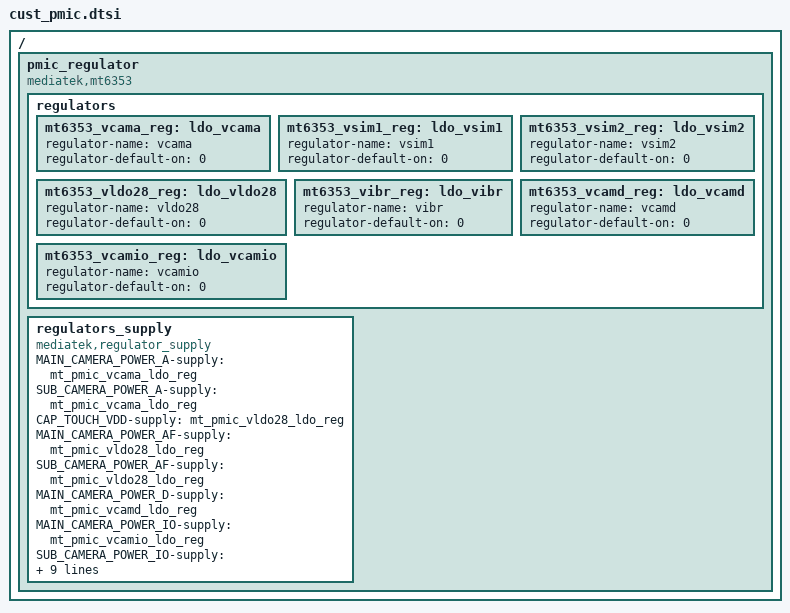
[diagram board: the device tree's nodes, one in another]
/*
 * Generated by MTK SP DrvGen Version 03.13.6 for MT6755. Copyright MediaTek Inc. (C) 2013.
 * Mon Aug 12 22:58:53 2019
 * Do Not Modify the File.
 */

/*************************
 * PMIC DTSI File
*************************/

/ {
	pmic_regulator {
		compatible = "mediatek,mt6353";
		/*reg = <0x01>*/
		regulators {
			mt6353_vcama_reg: ldo_vcama {
				regulator-name = "vcama";
				regulator-default-on = <0>; /* 0:skip, 1: off, 2:on */
			};
			mt6353_vsim1_reg: ldo_vsim1 {
				regulator-name = "vsim1";
				regulator-default-on = <0>; /* 0:skip, 1: off, 2:on */
			};
			mt6353_vsim2_reg: ldo_vsim2 {
				regulator-name = "vsim2";
				regulator-default-on = <0>; /* 0:skip, 1: off, 2:on */
			};
			mt6353_vldo28_reg: ldo_vldo28 {
				regulator-name = "vldo28";
				regulator-default-on = <0>; /* 0:skip, 1: off, 2:on */
			};
			mt6353_vibr_reg: ldo_vibr {
				regulator-name = "vibr";
				regulator-default-on = <0>; /* 0:skip, 1: off, 2:on */
			};
			mt6353_vcamd_reg: ldo_vcamd {
				regulator-name = "vcamd";
				regulator-default-on = <0>; /* 0:skip, 1: off, 2:on */
			};
			mt6353_vcamio_reg: ldo_vcamio {
				regulator-name = "vcamio";
				regulator-default-on = <0>; /* 0:skip, 1: off, 2:on */
			};
		};

		regulators_supply {
			compatible = "mediatek,regulator_supply";
			MAIN_CAMERA_POWER_A-supply = <&mt_pmic_vcama_ldo_reg>;
			SUB_CAMERA_POWER_A-supply = <&mt_pmic_vcama_ldo_reg>;
			CAP_TOUCH_VDD-supply = <&mt_pmic_vldo28_ldo_reg>;
			MAIN_CAMERA_POWER_AF-supply = <&mt_pmic_vldo28_ldo_reg>;
			SUB_CAMERA_POWER_AF-supply = <&mt_pmic_vldo28_ldo_reg>;
			MAIN_CAMERA_POWER_D-supply = <&mt_pmic_vcamd_ldo_reg>;
			MAIN_CAMERA_POWER_IO-supply = <&mt_pmic_vcamio_ldo_reg>;
			SUB_CAMERA_POWER_IO-supply = <&mt_pmic_vcamio_ldo_reg>;
			MAIN_CAMERA_POWER_A = "VCAMA";
			SUB_CAMERA_POWER_A = "VCAMA";
			CAP_TOUCH_VDD = "VLDO28";
			MAIN_CAMERA_POWER_AF = "VLDO28";
			SUB_CAMERA_POWER_AF = "VLDO28";
			MAIN_CAMERA_POWER_D = "VCAMD";
			MAIN_CAMERA_POWER_IO = "VCAMIO";
			SUB_CAMERA_POWER_IO = "VCAMIO";
		};
	};
};
